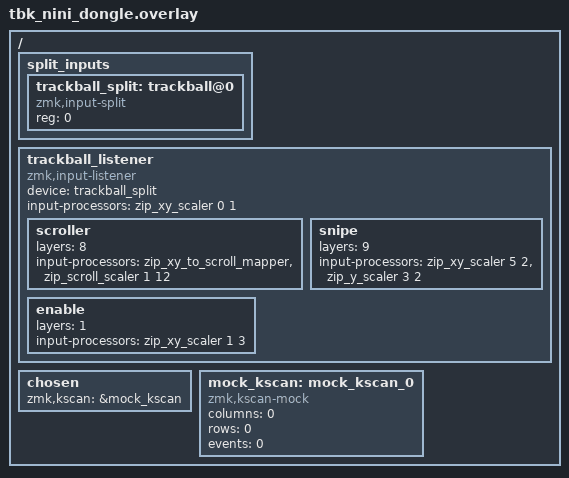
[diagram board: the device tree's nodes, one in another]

#include <input/processors.dtsi>
#include <dt-bindings/zmk/matrix_transform.h>


/ {
    split_inputs {
        #address-cells = <1>;
        #size-cells = <0>;

        trackball_split: trackball@0 {
            compatible = "zmk,input-split";
            reg = <0>;
        };
    };

    trackball_listener: trackball_listener {
        compatible = "zmk,input-listener";
        status = "okay";
        device = <&trackball_split>;
        input-processors = <&zip_xy_scaler 0 1>;

        scroller {
          layers = <8>;
          input-processors = <&zip_xy_to_scroll_mapper>, <&zip_scroll_scaler 1 12>;
        };

        snipe {
          layers = <9>;
          input-processors = <&zip_xy_scaler 5 2>, <&zip_y_scaler 3 2>;
        };

        enable {
          layers = <1>;
          input-processors = <&zip_xy_scaler 1 3>;
        };
        };

    chosen {
        zmk,kscan = &mock_kscan;
    };

    mock_kscan: mock_kscan_0 {
        compatible = "zmk,kscan-mock";
        columns = <0>;
        rows = <0>;
        events = <0>;
    };
};
